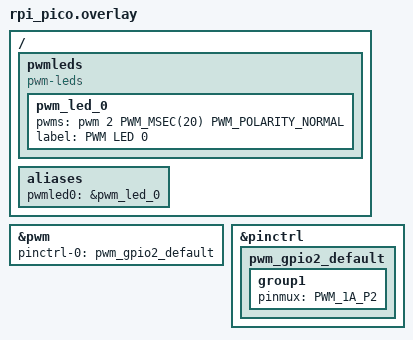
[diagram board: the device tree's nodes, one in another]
&pwm {
    status = "okay";
};

&pinctrl {
    pwm_gpio2_default: pwm_gpio2_default {
        group1 {
            pinmux = <PWM_1A_P2>;
        };
    };
};

&pwm {
    pinctrl-0 = <&pwm_gpio2_default>;
    pinctrl-names = "default";
};

/ {
    pwmleds {
        compatible = "pwm-leds";
        pwm_led_0: pwm_led_0 {
            pwms = <&pwm 2 PWM_MSEC(20) PWM_POLARITY_NORMAL>; // channel 0, 20ms period
            label = "PWM LED 0";
        };
    };

    aliases {
        pwmled0 = &pwm_led_0;
    };
};
